# DEBUGSS_WRAP_CTF_CFG_1_000760005000h register map
Vendor: Texas Instruments
Peripheral module from a debugger description file (folder AM275x).
Registers are 32-bit, read-only, reset 0x0 unless marked. A register's access mark holds for its fields unless they carry their own. Offsets are as the file gives them; lines under a group give offsets from that group; [hi:lo] are bit positions; {n}, {i} and the like mark numbered series; 'fields as' and 'values as' point back to an identical list; <NAME> marks a mode.

## ctf_cfg_1
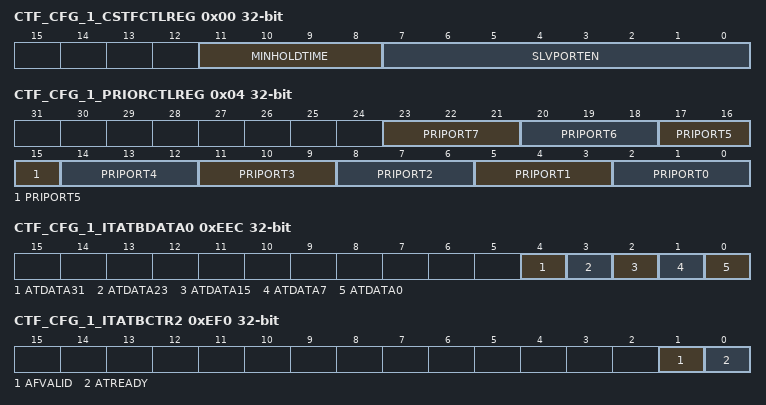
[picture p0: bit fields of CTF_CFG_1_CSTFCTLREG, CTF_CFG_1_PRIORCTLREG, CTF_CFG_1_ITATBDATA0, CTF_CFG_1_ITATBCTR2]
0x00 CTF_CFG_1_CSTFCTLREG access per field — It enables the target ports and defines the hold time of the target ports.
  [11:8] MINHOLDTIME rw — Minimum Hold time Hold time refers to the number of transactions that are output on the funnel initiator port from the same target while that target port ATVALIDSx is HIGH The CSTF holds for the minimum hold time and one additional cycle The maximum value that can be entered is 0xE and this equates to 15 cycles 0xF is reserved
  [7:0] SLVPORTEN rw — Target Port Enables Setting these bits enables the corresponding input, or target port If a bit is not set then this has the effect of excluding that port from the priority selection scheme
0x04 CTF_CFG_1_PRIORCTLREG access per field — Defines the order in which inputs are selected. This register must only be altered when the trace sources are off and the system is drained.
  [23:21] PRIPORT7 rw — Priority value of the eighth target port Highest priority goes to the lowest value
  [20:18] PRIPORT6 rw — Priority value of the seventh target port Highest priority goes to the lowest value
  [17:15] PRIPORT5 rw — Priority value of the sixth target port Highest priority goes to the lowest value
  [14:12] PRIPORT4 rw — Priority value of the fifth target port Highest priority goes to the lowest value
  [11:9] PRIPORT3 rw — Priority value of the fourth target port Highest priority goes to the lowest value
  [8:6] PRIPORT2 rw — Priority value of the third target port Highest priority goes to the lowest value
  [5:3] PRIPORT1 rw — Priority value of the second target port Highest priority goes to the lowest value
  [2:0] PRIPORT0 rw — Priority value of the first target port Highest priority goes to the lowest value
0xEEC CTF_CFG_1_ITATBDATA0 access per field — Integration Test Register.
  [4] ATDATA31 rw — A write outputs data on ATDATAM[31] A read returns the value of ATDATAS[31]
  [3] ATDATA23 rw — A write outputs data on ATDATAM[23] A read returns the value of ATDATAS[23]
  [2] ATDATA15 rw — A write outputs data on ATDATAM[15] A read returns the value of ATDATAS[15]
  [1] ATDATA7 rw — A write outputs data on ATDATAM[7] A read returns the value of ATDATAS[7]
  [0] ATDATA0 rw — A write outputs data on ATDATAM[0] A read returns the value of ATDATAS[0]
0xEF0 CTF_CFG_1_ITATBCTR2 access per field — Integration Test Control Register 2.
  [1] AFVALID rw — Reading this bit returns the value of AFVALIDM Writing this bit sets the AFVALIDS[n] bit where n is enabled by the CSTFCTLREG
  [0] ATREADY rw — Reading this bit returns the value of ATREADYM Writing this bit sets the AFREADYS[n] bit where n is enabled by the CSTFCTLREG
0xEF4 CTF_CFG_1_ITATBCTR1 access per field — Integration Test Control Register 1.
  [5:0] ATID rw — Writing this register sets the value of ATIDM Reading it returns the value of ATIDS
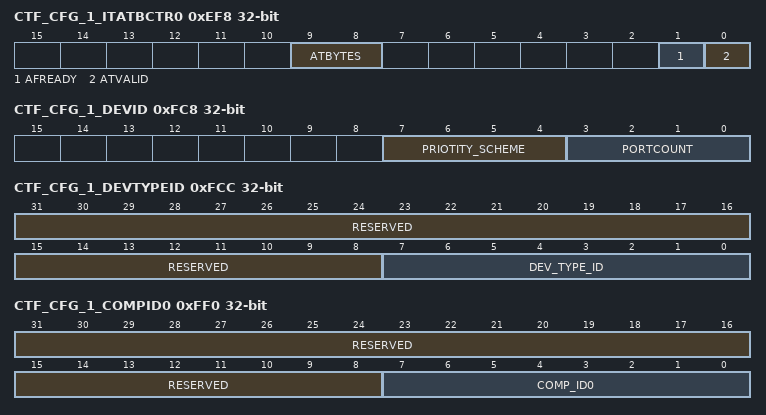
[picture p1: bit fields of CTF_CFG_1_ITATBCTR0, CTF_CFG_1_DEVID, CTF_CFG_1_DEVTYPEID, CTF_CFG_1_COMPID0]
0xEF8 CTF_CFG_1_ITATBCTR0 access per field — Integration Test Control Register 0.
  [9:8] ATBYTES rw — Writing this field sets the value of ATBYTESM Reading it returns the value of ATBYTSS[n]
  [1] AFREADY rw — Writing this field sets the value of AFREADYM Reading it returns the value of AFREADYS[n]
  [0] ATVALID rw — Writing this field sets the value of ATVALIDM Reading it returns the value of ATVALIDS[n]
0xF00 CTF_CFG_1_INTCTRL access per field — Integration Mode Register
  [0] INTEGMODEN rw — Integration Mode Enable
0xFA0 CTF_CFG_1_CTSET access per field — Claim Tag Set Register
  [3:0] CLAIM_TAG_SET rw
0xFA4 CTF_CFG_1_CTCLR access per field — Claim Tag Clear Register
  [3:0] CLAIM_TAG_CLEAR rw
0xFB0 CTF_CFG_1_LAREG rw — Software must write 0xCSACCE55 to this register in order for application to gain access to the other registers. If paddrdbg31 is high, this is ignored.
  [31:0] LOCK_ACCESS_REGISTER
0xFB4 CTF_CFG_1_LSREG — The CTI implements two memory maps controlled through PADDRDBG31. When PADDRDBG31 is HIGH, the Lock Status Register reads as 0x0 indicating that no lock exists. When PADDRDBG31 is LOW, the Lock Status Register reads as 0x3 from reset. This indicates a 32-bit lock access mechanism is present and is locked
  [1:0] LOCK_STATUS — The CTI implements two memory maps controlled through PADDRDBG31 When PADDRDBG31 is HIGH, the Lock Status Register reads as 0x0 indicating that no lock exists When PADDRDBG31 is LOW, the Lock Status Register reads as 0x3 from reset This indicates a 32-bit lock access mechanism is present and is locked Application must write to the LAREG to gain access
0xFB8 CTF_CFG_1_AUTHST — Reports the required security level.
  [3:0] AUTHENTICATION_STATUS — Reports the required security level bit 0 indicates Invasive Debug Controlled and bit 1 is the current value Bit 2 indicates non-invasive debug controlled and bit 3 is the current value Returns 0x5
0xFC8 CTF_CFG_1_DEVID — Device ID Register
  [7:4] PRIOTITY_SCHEME — The CSTF implements a static priority scheme Value = 0x2
  [3:0] PORTCOUNT — This is the value of the Verilog define PORTCOUNT and represents the number of input ports connected By default all 8 ports are connected 0x0 and 0x1 are illegal values
0xFCC CTF_CFG_1_DEVTYPEID — Device Type Identifier Register
  [31:8] RESERVED — Reserveed, returns 0
  [7:0] DEV_TYPE_ID — A value of 0x12 identifies this device as a trace link [0x2] and specifically as a funnel/router [0x1]
0xFD0 CTF_CFG_1_PERID4 — Peripheral ID4 Register
  [7:0] PERIPH_ID4 — Peripheral ID 4, returns 0x4
{0xFC0+4i} CTF_CFG_1_PERID{i} (i=5..7) — Peripheral ID{i} Register
  [7:0] PERIPH_ID{i} — Peripheral ID {i}, returns 0x0
0xFE0 CTF_CFG_1_PERID0 — Peripheral ID0 Register
  [7:0] PERIPH_ID0 — Perpiheral ID 0, returns 0x06
0xFE4 CTF_CFG_1_PERID1 — Peripheral ID1 Register
  [7:0] PERIPH_ID1 — Peripheral ID 1, returns 0xB9
0xFE8 CTF_CFG_1_PERID2 — Peripheral ID2 Register
  [7:0] PERIPH_ID2 — Peripheral ID 2, returns 9x2B
0xFEC CTF_CFG_1_PERID3 — Peripheral ID3 Register
  [7:0] PERPIH_ID3 — Peripheral ID3 register, returns 0x00
0xFF0 CTF_CFG_1_COMPID0 — Component ID0 Register
  [31:8] RESERVED — Read returns 0
  [7:0] COMP_ID0 — A component identification register, that indicates that the identification registers are present This register also indicates the component class
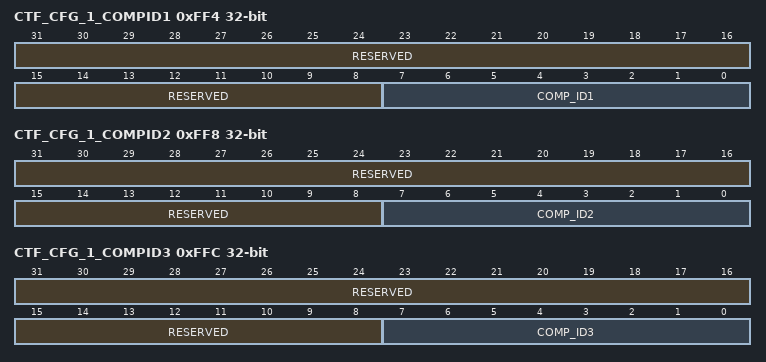
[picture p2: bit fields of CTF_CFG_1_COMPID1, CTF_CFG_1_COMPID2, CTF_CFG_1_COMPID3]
0xFF4 CTF_CFG_1_COMPID1 — Component ID1 Register
  [31:8] RESERVED — Read returns 0
  [7:0] COMP_ID1 — A component identification register, that indicates that the identification registers are present This register also indicates the component class
0xFF8 CTF_CFG_1_COMPID2 — Component ID2 Register
  [31:8] RESERVED — Returns 0
  [7:0] COMP_ID2 — A component identification register, that indicates that the identification registers are present This register also indicates the component class
0xFFC CTF_CFG_1_COMPID3 — Component ID3 Register
  [31:8] RESERVED — returns 0 when read
  [7:0] COMP_ID3 — A component identification register, that indicates that the identification registers are present This register also indicates the component class
